# ECM3532 register map
Vendor: EtaCompute; Series: ECM35xx; File version: 1.0.0
CPU: CM3 r1p1, little endian, MPU, no FPU, 3 interrupt priority bits
Registers are 32-bit, read-write, reset 0x0 unless marked. A register's access mark holds for its fields unless they carry their own. Offsets are from the block's base; [hi:lo] are bit positions; {n}, {i} and the like mark numbered series.

## DSPCTRL_M3 — These registers control the DSP complex.
Base 0x40800000
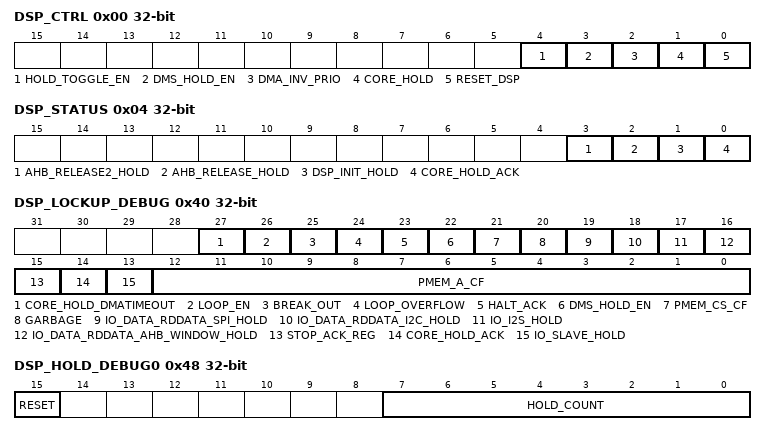
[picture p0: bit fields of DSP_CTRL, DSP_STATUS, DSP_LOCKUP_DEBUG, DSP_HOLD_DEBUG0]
0x00 DSP_CTRL — DSP Control register
  [4] HOLD_TOGGLE_EN — This is a purely debug feature that effectively emulates a very fast series of writes to RELEASE_HOLD_PULSE. So by setting this field (and DSP_CTRL.CORE_HOLD), the DSP will run approximately 1/3 slower and be affected by a series of holds. Useful for testing responses to unexpected hold cases.
  [3] DMS_HOLD_EN — From NXP doc: Controls the function of the core_hold input. When dms_hold_en is high, a high on core_hold puts the entire CoolFlux DSP into the hold state (same as io_hold). When dms_hold_en is low, a high on core_hold puts the entire CoolFlux DSP except the DMS block into the hold state; the DMS block remains John's translation: setting dms_hold_en and core_hold stops everything and would likely PREVENT PMEM, XMEM, YMEM access.
  [2] DMA_INV_PRIO — If set to 1, the DMA and AHB have highest priority access to the PMEM, XMEM and YMEM. If set to 0, the DSP Core typically has priority (note the DSP has a timeout capability that can override this setting).
  [1] CORE_HOLD — Setting this bit places the DSP in hold. To confirm it is in hold, look at the core_hold_ack bit in the dsp_status. dma_hold_en affects how this bit is interpreted. Theoretically, setting this bit and then clearing it should allow the DSP to pause and then restart.
  [0] RESET_DSP — Setting this bit resets most of the DSP Core and holds it in a reset state. When this is high and the DSP complex is out of reset, the AHB has access to PMEM, XMEM and YMEM without the DSP attempting to access those memories.
0x04 DSP_STATUS
  [3] AHB_RELEASE2_HOLD ro — Live value of toggle hold enabled by DSP_CTRL.HOLD_TOGGLE_EN. When this bit is one, the core is in HOLD, while zero the core is running.
  [2] AHB_RELEASE_HOLD ro — Live value of core_hold_ack from DSP Core. When it is one, the core is safely in HOLD.
  [1] DSP_INIT_HOLD — This bit is set by the DSP when it wants to initiate a hold (dsp_hold) or by DSP debug logic when it detects a warning in AHB window control register dsp_status and the control_status.warn_to_hold is set. It is cleared by writing a 1 to this location, presumably after debugging is complete. To determine what initiated the hold, read the DSP IOMEM register CONFIG_STATUS.
  [0] CORE_HOLD_ACK ro — Live value of core_hold_ack from DSP Core. When it is one, the core is safely in HOLD.
0x08 RELEASE_HOLD_PULSE — This debug register allows for single instruction stepping from the outside for debug purposes. To use it, first assert core_hold (DSP_CTRL.CORE_HOLD). Then write any value to this register, which will cause the core_hold to be temporarily driven low. Note that the logic waits for core_hold_ack to deassert before it reasserts core_hold, which should allow for one instruction to complete. This allows for single instruciton sequences.
  [31:0] DATA — Any write will pulse HOLD low.
0x20 DMA_SRCRDY_12 — CSR bit for DSP DMA engine. Accessible from AHB Slave and DSP IOBUS and useable by DMA as a Source Ready.
  [0] READY — Write a 1 to mark this as ready.
0x24 DMA_SRCRDY_13 — CSR bit for DSP DMA engine. Accessible from AHB Slave and DSP IOBUS and useable by DMA as a Source Ready.
  [0] READY — Write a 1 to mark this as ready.
0x28 DMA_SRCRDY_14 — CSR bit for DSP DMA engine. Accessible from AHB Slave and DSP IOBUS and useable by DMA as a Source Ready.
  [0] READY — Write a 1 to mark this as ready.
0x2C DMA_SRCRDY_15 — CSR bit for DSP DMA engine. Accessible from AHB Slave and DSP IOBUS and useable by DMA as a Source Ready.
  [0] READY — Write a 1 to mark this as ready.
{0x0+4i} DMA_DSTRDY_{i} (i=12..15) — CSR bit for DSP DMA engine. Accessible from AHB Slave and DSP IOBUS and useable by DMA as a Destination Ready.
  [0] READY — Write a 1 to mark this as ready.
0x40 DSP_LOCKUP_DEBUG — Provides basic information about the current DSP state and possible sources of lockups.
  [27] CORE_HOLD_DMATIMEOUT ro
  [26] LOOP_EN ro
  [25] BREAK_OUT ro
  [24] LOOP_OVERFLOW ro
  [23] HALT_ACK ro
  [22] DMS_HOLD_EN ro
  [21] PMEM_CS_CF ro
  [20] GARBAGE ro — garbage(reads are unknown)
  [19] IO_DATA_RDDATA_SPI_HOLD ro
  [18] IO_DATA_RDDATA_I2C_HOLD ro
  [17] IO_I2S_HOLD ro
  [16] IO_DATA_RDDATA_AHB_WINDOW_HOLD ro
  [15] STOP_ACK_REG ro
  [14] CORE_HOLD_ACK ro
  [13] IO_SLAVE_HOLD ro
  [12:0] PMEM_A_CF ro
0x44 DSP_STACK_DEBUG1 — Provides information about Maximum Stack Used. Setup by DSP, but readable from both DSP and M3.
  [14:0] MAX_STACK_ADDR ro — Read only register that indicates the maximum stack address used. Since stack starts at address 0, this should indicate the max stack used. Note this is expressed as halfwords (2 bytes).
0x48 DSP_HOLD_DEBUG0 — Controls for measuring how much time core spends in hold waiting for peripheral to respond.
  [15] RESET — If 1, places HOLD_COUNT logic in reset. Set to 0 to start counting holds. Note, this can be writte or read from DSPCTRL_DSP or DSPCTRL_M3.
  [7:0] HOLD_COUNT ro — Records the max number of holds detected in 256 clock cycle sample time. Holds can be due to peripherals (including DMA access to peripherals) or other mechianms like WARN signals or CSR holds. Counts both HOLD and HOLD_ACK signals. Hyper technicality, the real number is (1+HOLD_COUNT) over 257 cycles since a hold starts the counter.
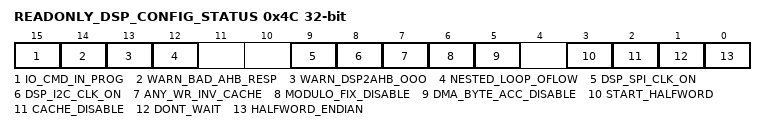
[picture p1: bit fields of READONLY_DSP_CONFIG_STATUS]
0x4C READONLY_DSP_CONFIG_STATUS — This is a read only copy of the DSP Config status register intended to provide M3 access if the DSP is in hold.
  [15] IO_CMD_IN_PROG ro — If 1, there are transactions (read or write) ongoing on the AHB Window interface. By polling this bit for a zero and ensuring no DMA traffic is active, the processor can determine when it can change the AHB window(s) without affecting in flight transactions.
  [14] WARN_BAD_AHB_RESP ro — This is a read-only copy of a DSP WARNING bit. If warn_to_hold is set, this can cause a DSP hold event. This is a sticky bit that collects all nonzero AHB responses and stores it here. AHB non-zero responses are generally errors. We do not track the specific command that resulted in the error. These errors should generally be rare are are most often the result of a bad address. The sticky bit can be cleared by writing a 1 the corresponding location in the DSP register CONFIG_STATUS (after clearing any holds)
  [13] WARN_DSP2AHB_OOO ro — This is a read-only copy of a DSP WARNING bit. If warn_to_hold is set, this can cause a DSP hold event. This is a sticky bit indicating that a DSP client (DSP Core or DMA Channel) did not follow the prescribed write sequence described in the DSP User Guide under "32 bit Write Accesses", that is, it did not write an even address followed by an odd address (or reversed if START_HALFWORD is set). The sticky bit can be cleared by writing a 1 the corresponding location in the DSP register CONFIG_STATUS (after clearing any holds)
  [12] NESTED_LOOP_OFLOW ro — This is a read-only copy of a DSP WARNING bit. If warn_to_hold is set, this can cause a DSP hold event. This is a sticky bit indicating that the DSP Core Nested Loop HW has suffered an overflow. The sticky bit can be cleared by writing a 1 the corresponding location in the DSP register CONFIG_STATUS (after clearing any holds)
  [9] DSP_SPI_CLK_ON ro — If 0, the 8MHz clock to the SPI is only enabled once the local SM determines it is needed. This is the lowest power setting, but requires some spin up time for every DMA or DSP Core access (typically ~500-625ns). If 1, the 8MHz clock is always running, which is higher power but quicker response time.
  [8] DSP_I2C_CLK_ON ro — If 0, the 8MHz clock to the I2C is only enabled once the local SM determines it is needed. This is the lowest power setting, but requires some spin up time for every DMA or DSP Core access (typically ~500-625ns). If 1, the 8MHz clock is always running, which is higher power but quicker response time.
  [7] ANY_WR_INV_CACHE ro — Normally, the cache is invalidated by a write to the cache line. If this bit is set, any write will invalidate the cache line. This may be useful if a write changes the data (e.g. popping a FIFO), but if set the read cache may be disabled (or less effective) on a M3 to M3 DMA transfer.
  [6] MODULO_FIX_DISABLE ro — If this bit is set, it disables the Modulo Fix which doubles the number of nested loops. This is intended as a debug bit and it has no functional use.
  [5] DMA_BYTE_ACC_DISABLE ro — If this bit is set, it disables the DMA byte access functionality. This is intended as a debug bit and it has no functional use.
  [3] START_HALFWORD ro — This bit controls when the AHB command is issued on the AHB Window bus. Typically this bit is set the same as halfword_endian. 0 - AHB write begins when odd address is written. 1 - AHB write begins when even address is written.
  [2] CACHE_DISABLE ro — If set to 1, it disables the 16 bit halfword cache. This will cause every 16 bit read to result in a 32 bit read on the AHB bus.
  [1] DONT_WAIT ro — Debug option that causes every 16 bit write on the DSP to result in a 16 bit access on the 32 bit AHB Window bus with HSIZE indicating it is a 2 byte access.
  [0] HALFWORD_ENDIAN ro — This bit swaps the endianness of 16 bit halfwords as they appear on the AHB bus and which DSP write starts the AHB write. Typically this bit is set the same as halfword_endian. 0 - DSP data appears on AHB Window bus[31:0]={odd_data, even_data} 1 - DSP data appears on AHB Window bus[31:0]={even_data, odd_data}
{0x21030+4i} SEMAPHORE{i} (i=0..3) — The semaphores are implemented to provide a mechanism for coordination between the DSP Core and any other AHB Masters accessing the IOMEM space. The intent of the semaphores was to arbitrate usage of the DMA Channels, but the semaphores are general purpose and be used as FW sees fit. To reserve a semaphore, read the register. If it is a zero, the accessing client has just grabbed the semaphore. Future reads by any client will show this bit to be a 1. Once a client is done with the semaphore, it can release it by writing a 1 to the bit location. Note that any client can release any semaphore reserved by any other client.
  [0] SEMAPHORE — See register description for details.
